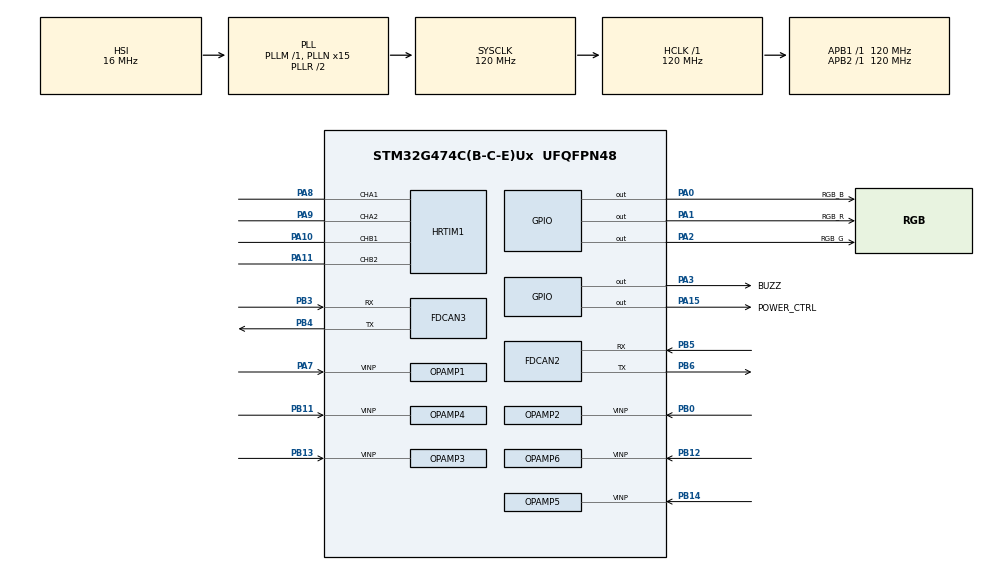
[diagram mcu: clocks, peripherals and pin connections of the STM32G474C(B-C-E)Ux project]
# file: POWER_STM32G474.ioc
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ADC1.Channel-1\#ChannelRegularConversion=ADC_CHANNEL_VOPAMP1
ADC1.NbrOfConversionFlag=1
ADC1.OffsetNumber-1\#ChannelRegularConversion=ADC_OFFSET_NONE
ADC1.Rank-1\#ChannelRegularConversion=1
ADC1.SamplingTime-1\#ChannelRegularConversion=ADC_SAMPLETIME_2CYCLES_5
ADC1.master=1
ADC2.Channel-0\#ChannelRegularConversion=ADC_CHANNEL_VOPAMP2
ADC2.NbrOfConversionFlag=1
ADC2.OffsetNumber-0\#ChannelRegularConversion=ADC_OFFSET_NONE
ADC2.Rank-0\#ChannelRegularConversion=1
ADC2.SamplingTime-0\#ChannelRegularConversion=ADC_SAMPLETIME_2CYCLES_5
ADC3.Channel-0\#ChannelRegularConversion=ADC_CHANNEL_VOPAMP3_ADC3
ADC3.NbrOfConversionFlag=1
ADC3.OffsetNumber-0\#ChannelRegularConversion=ADC_OFFSET_NONE
ADC3.Rank-0\#ChannelRegularConversion=1
ADC3.SamplingTime-0\#ChannelRegularConversion=ADC_SAMPLETIME_2CYCLES_5
ADC3.master=1
ADC4.Channel-0\#ChannelRegularConversion=ADC_CHANNEL_VOPAMP6
ADC4.NbrOfConversionFlag=1
ADC4.OffsetNumber-0\#ChannelRegularConversion=ADC_OFFSET_NONE
ADC4.Rank-0\#ChannelRegularConversion=1
ADC4.SamplingTime-0\#ChannelRegularConversion=ADC_SAMPLETIME_2CYCLES_5
ADC5.Channel-0\#ChannelRegularConversion=ADC_CHANNEL_VOPAMP5
ADC5.NbrOfConversionFlag=1
ADC5.OffsetNumber-0\#ChannelRegularConversion=ADC_OFFSET_NONE
ADC5.Rank-0\#ChannelRegularConversion=1
ADC5.SamplingTime-0\#ChannelRegularConversion=ADC_SAMPLETIME_2CYCLES_5
FDCAN2.CalculateBaudRateNominal=1000000
FDCAN2.CalculateTimeBitNominal=1000
FDCAN2.CalculateTimeQuantumNominal=25.0
FDCAN2.DataSyncJumpWidth=2
FDCAN2.DataTimeSeg1=13
FDCAN2.DataTimeSeg2=2
FDCAN2.ExtFiltersNbr=4
FDCAN2.NominalPrescaler=3
FDCAN2.NominalSyncJumpWidth=20
FDCAN2.NominalTimeSeg1=29
FDCAN2.NominalTimeSeg2=10
FDCAN2.StdFiltersNbr=4
FDCAN3.CalculateBaudRateNominal=1000000
FDCAN3.CalculateTimeBitNominal=1000
FDCAN3.CalculateTimeQuantumNominal=25.0
FDCAN3.DataSyncJumpWidth=2
FDCAN3.DataTimeSeg1=13
FDCAN3.DataTimeSeg2=2
FDCAN3.ExtFiltersNbr=4
FDCAN3.NominalPrescaler=3
FDCAN3.NominalSyncJumpWidth=20
FDCAN3.NominalTimeSeg1=29
FDCAN3.NominalTimeSeg2=10
FDCAN3.StdFiltersNbr=4
Mcu.Family=STM32G4
Mcu.Name=STM32G474C(B-C-E)Ux
Mcu.Package=UFQFPN48
NVIC.PriorityGroup=NVIC_PRIORITYGROUP_4
OPAMP6.PowerMode=OPAMP_POWERMODE_HIGHSPEED
PA0.GPIO_Label=RGB_B
PA0.Signal=GPIO_Output
PA1.GPIO_Label=RGB_R
PA1.Signal=GPIO_Output
PA10.Mode=Output_TB1TB2
PA10.Signal=HRTIM1_CHB1
PA11.Mode=Output_TB1TB2
PA11.Signal=HRTIM1_CHB2
PA13.Mode=Serial_Wire
PA13.Signal=SYS_JTMS-SWDIO
PA14.Mode=Serial_Wire
PA14.Signal=SYS_JTCK-SWCLK
PA15.GPIO_Label=POWER_CTRL
PA15.Signal=GPIO_Output
PA2.GPIO_Label=RGB_G
PA2.Signal=GPIO_Output
PA3.GPIO_Label=BUZZ
PA3.Signal=GPIO_Output
PA7.Mode=Follower_Internally_Connected
PA7.Signal=OPAMP1_VINP
PA8.Mode=Output_TA1TA2
PA8.Signal=HRTIM1_CHA1
PA9.Mode=Output_TA1TA2
PA9.Signal=HRTIM1_CHA2
PB0.Mode=Follower_Internally_Connected
PB0.Signal=OPAMP2_VINP
PB11.Mode=Follower_Internally_Connected
PB11.Signal=OPAMP4_VINP
PB12.Mode=Follower_Internally_Connected
PB12.Signal=OPAMP6_VINP
PB13.Mode=Follower_Internally_Connected
PB13.Signal=OPAMP3_VINP
PB14.Mode=Follower_Internally_Connected
PB14.Signal=OPAMP5_VINP
PB3.Mode=FDCAN_Activate
PB3.Signal=FDCAN3_RX
PB4.Mode=FDCAN_Activate
PB4.Signal=FDCAN3_TX
PB5.Mode=FDCAN_Activate
PB5.Signal=FDCAN2_RX
PB6.Mode=FDCAN_Activate
PB6.Signal=FDCAN2_TX
ProjectManager.HeapSize=0x200
ProjectManager.StackSize=0x400
ProjectManager.TargetToolchain=MDK-ARM V5.32
RCC.ADC12Freq_Value=120000000
RCC.ADC345Freq_Value=120000000
RCC.AHBFreq_Value=120000000
RCC.APB1Freq_Value=120000000
RCC.APB1TimFreq_Value=120000000
RCC.APB2Freq_Value=120000000
RCC.APB2TimFreq_Value=120000000
RCC.CortexFreq_Value=120000000
RCC.EXTERNAL_CLOCK_VALUE=12288000
RCC.HCLKFreq_Value=120000000
RCC.HSE_VALUE=24000000
RCC.HSI48_VALUE=48000000
RCC.HSI_VALUE=16000000
RCC.LSE_VALUE=32768
RCC.PLLN=15
RCC.SYSCLKFreq_VALUE=120000000
RCC.SYSCLKSource=RCC_SYSCLKSOURCE_PLLCLK
RCC.USBFreq_Value=120000000
RCC.VCOOutputFreq_Value=240000000
VP_ADC1_OPAMP_INTERNAL1.Mode=IN-OPAMP1
VP_ADC2_OPAMP_INTERNAL2.Mode=IN-OPAMP2
VP_ADC3_OPAMP_INTERNAL3.Mode=IN-OPAMP3
VP_ADC4_OPAMP_INTERNAL6.Mode=IN-OPAMP6
VP_ADC5_OPAMP_INTERNAL4.Mode=IN-OPAMP4
VP_ADC5_OPAMP_INTERNAL5.Mode=IN-OPAMP5
VP_FMAC_VS_FMAC.Mode=FMAC_Activate
VP_HRTIM1_VS_hrtimMasterTimerNoOutput.Mode=MasterTimer
VP_SYS_VS_DBSignals.Mode=DisableDeadBatterySignals
board=custom

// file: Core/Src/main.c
/* USER CODE BEGIN Header */
/**
  ******************************************************************************
  * @file           : main.c
  * @brief          : Main program body
  ******************************************************************************
  * @attention
  *
  * Copyright (c) 2025 STMicroelectronics.
  * All rights reserved.
  *
  * This software is licensed under terms that can be found in the LICENSE file
  * in the root directory of this software component.
  * If no LICENSE file comes with this software, it is provided AS-IS.
  *
  ******************************************************************************
  */
/* USER CODE END Header */
#include "main.h"
#include "adc.h"
#include "fdcan.h"
#include "fmac.h"
#include "hrtim.h"
#include "opamp.h"
#include "gpio.h"

/* USER CODE BEGIN Includes */
#include "bsp_fdcan.h"
/* USER CODE END Includes */

void SystemClock_Config(void);

/* USER CODE BEGIN 0 */
uint8_t tx_data[8] = {0,1,2,3,4,5,6,7};
/* USER CODE END 0 */

int main(void)
{

  /* MCU Configuration--------------------------------------------------------*/

  /* Reset of all peripherals, Initializes the Flash interface and the Systick. */
  HAL_Init();

  /* Configure the system clock */
  SystemClock_Config();

  /* Initialize all configured peripherals */
  MX_GPIO_Init();
  MX_ADC1_Init();
  MX_FDCAN3_Init();
  MX_HRTIM1_Init();
  MX_ADC2_Init();
  MX_ADC3_Init();
  MX_ADC4_Init();
  MX_ADC5_Init();
  MX_FMAC_Init();
  MX_OPAMP1_Init();
  MX_OPAMP2_Init();
  MX_OPAMP3_Init();
  MX_OPAMP4_Init();
  MX_OPAMP5_Init();
  MX_OPAMP6_Init();
  MX_FDCAN2_Init();

  /* Infinite loop */
  /* USER CODE BEGIN WHILE */
  while (1)
  {
//		fdcanx_send_data(&hfdcan1, 0x520, tx_data, 8);
//		HAL_Delay(100);
//
		fdcanx_send_data(&hfdcan2, 0x520, tx_data, 8);
		HAL_Delay(100);

		fdcanx_send_data(&hfdcan3, 0x520, tx_data, 8);
		HAL_Delay(100);
    /* USER CODE END WHILE */

  }
}

void SystemClock_Config(void)
{
  RCC_OscInitTypeDef RCC_OscInitStruct = {0};
  RCC_ClkInitTypeDef RCC_ClkInitStruct = {0};

  /** Configure the main internal regulator output voltage
  */
  HAL_PWREx_ControlVoltageScaling(PWR_REGULATOR_VOLTAGE_SCALE1);

  /** Initializes the RCC Oscillators according to the specified parameters
  * in the RCC_OscInitTypeDef structure.
  */
  RCC_OscInitStruct.OscillatorType = RCC_OSCILLATORTYPE_HSI;
  RCC_OscInitStruct.HSIState = RCC_HSI_ON;
  RCC_OscInitStruct.HSICalibrationValue = RCC_HSICALIBRATION_DEFAULT;
  RCC_OscInitStruct.PLL.PLLState = RCC_PLL_ON;
  RCC_OscInitStruct.PLL.PLLSource = RCC_PLLSOURCE_HSI;
  RCC_OscInitStruct.PLL.PLLM = RCC_PLLM_DIV1;
  RCC_OscInitStruct.PLL.PLLN = 15;
  RCC_OscInitStruct.PLL.PLLP = RCC_PLLP_DIV2;
  RCC_OscInitStruct.PLL.PLLQ = RCC_PLLQ_DIV2;
  RCC_OscInitStruct.PLL.PLLR = RCC_PLLR_DIV2;
  if (HAL_RCC_OscConfig(&RCC_OscInitStruct) != HAL_OK)
  {
    Error_Handler();
  }

  /** Initializes the CPU, AHB and APB buses clocks
  */
  RCC_ClkInitStruct.ClockType = RCC_CLOCKTYPE_HCLK|RCC_CLOCKTYPE_SYSCLK
                              |RCC_CLOCKTYPE_PCLK1|RCC_CLOCKTYPE_PCLK2;
  RCC_ClkInitStruct.SYSCLKSource = RCC_SYSCLKSOURCE_PLLCLK;
  RCC_ClkInitStruct.AHBCLKDivider = RCC_SYSCLK_DIV1;
  RCC_ClkInitStruct.APB1CLKDivider = RCC_HCLK_DIV1;
  RCC_ClkInitStruct.APB2CLKDivider = RCC_HCLK_DIV1;

  if (HAL_RCC_ClockConfig(&RCC_ClkInitStruct, FLASH_LATENCY_3) != HAL_OK)
  {
    Error_Handler();
  }
}

void Error_Handler(void)
{
  __disable_irq();
  while (1)
  {
  }
}
